# R9A09G057H register map
Vendor: Renesas Electronics; File version: 1.00
CPU: other r0p3, little endian, MPU, FPU, vendor SysTick, 4 interrupt priority bits, 480 interrupts
Registers are 32-bit, read-write, no defined reset value unless marked. A register's access mark holds for its fields unless they carry their own. Offsets are from the block's base; [hi:lo] are bit positions; lines under a group give offsets from that group; {n}, {i} and the like mark numbered series.

## R_SCIFA0 — IO define file for scifa.
Base 0x11C01400
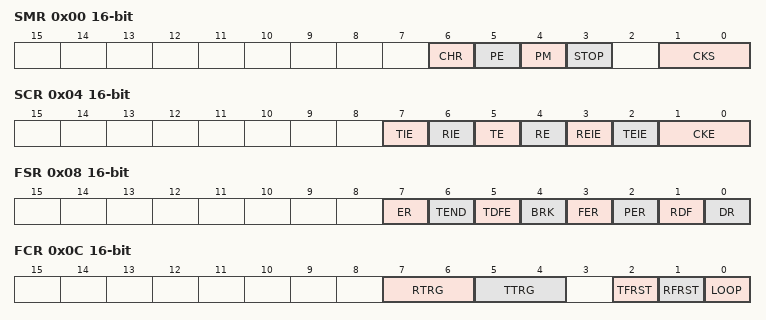
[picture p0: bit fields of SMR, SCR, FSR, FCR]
0x00 SMR 16-bit
  [6] CHR, [5] PE, [4] PM, [3] STOP, [1:0] CKS
0x02 MDDR 8-bit
0x02 BRR 8-bit
0x04 SCR 16-bit
  [7] TIE, [6] RIE, [5] TE, [4] RE, [3] REIE, [2] TEIE, [1:0] CKE
0x06 FTDR 8-bit wo
0x08 FSR 16-bit
  [7] ER, [6] TEND, [5] TDFE, [4] BRK, [3] FER ro, [2] PER ro, [1] RDF, [0] DR
0x0A FRDR 8-bit ro
0x0C FCR 16-bit
  [7:6] RTRG, [5:4] TTRG, [2] TFRST, [1] RFRST, [0] LOOP
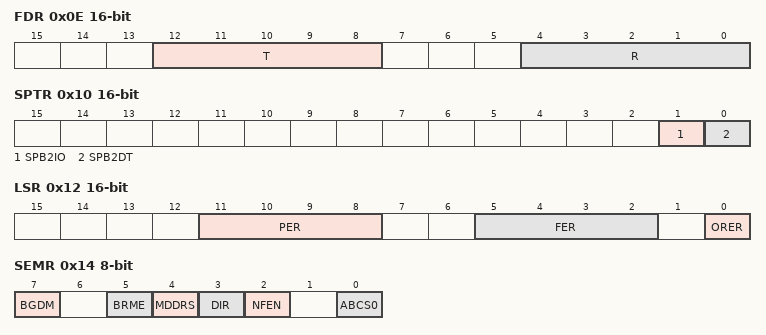
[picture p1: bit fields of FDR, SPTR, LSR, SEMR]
0x0E FDR 16-bit ro
  [12:8] T, [4:0] R
0x10 SPTR 16-bit
  [1] SPB2IO, [0] SPB2DT
0x12 LSR 16-bit
  [11:8] PER ro, [5:2] FER ro, [0] ORER
0x14 SEMR 8-bit
  [7] BGDM, [5] BRME, [4] MDDRS, [3] DIR, [2] NFEN, [0] ABCS0
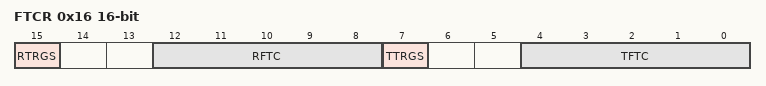
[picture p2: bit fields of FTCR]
0x16 FTCR 16-bit
  [15] RTRGS, [12:8] RFTC, [7] TTRGS, [4:0] TFTC

## R_SPIBSC — IO define file for spibsc.
Base 0x40060000
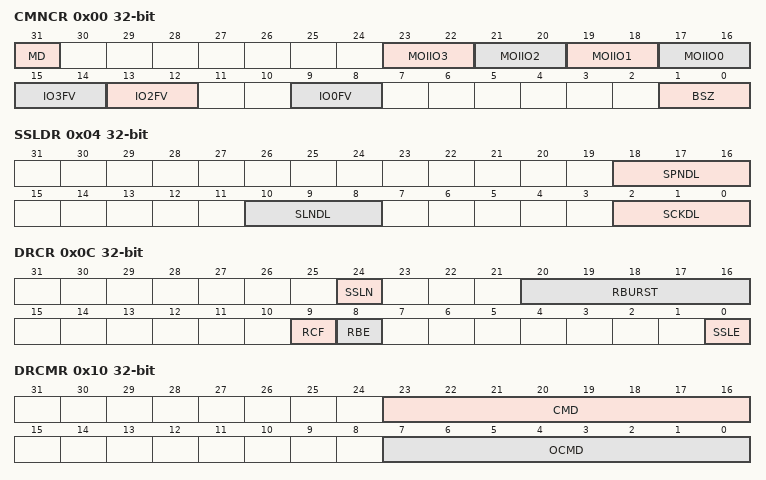
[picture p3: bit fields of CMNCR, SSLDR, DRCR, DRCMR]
0x00 CMNCR
  [31] MD, [2n+17:2n+16] MOIIO{n} (n=0..3), [15:14] IO3FV, [13:12] IO2FV, [9:8] IO0FV, [1:0] BSZ
0x04 SSLDR
  [18:16] SPNDL, [10:8] SLNDL, [2:0] SCKDL
0x0C DRCR
  [24] SSLN wo, [20:16] RBURST, [9] RCF wo, [8] RBE, [0] SSLE
0x10 DRCMR
  [23:16] CMD, [7:0] OCMD
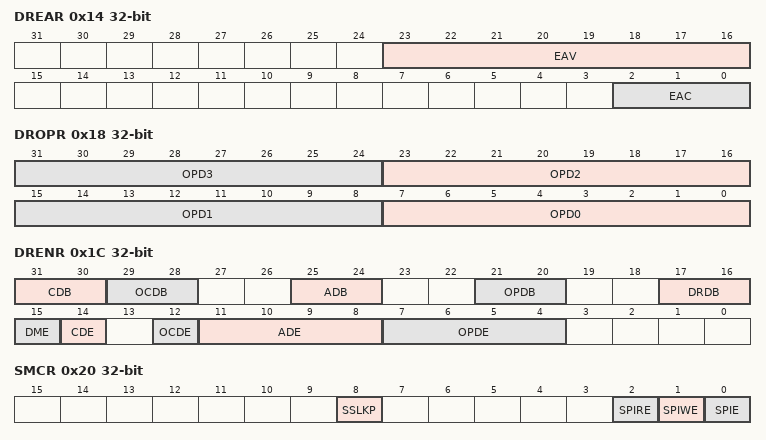
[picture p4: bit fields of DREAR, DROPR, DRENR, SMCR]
0x14 DREAR
  [23:16] EAV, [2:0] EAC
0x18 DROPR
  [8n+7:8n] OPD{n} (n=0..3)
0x1C DRENR
  [31:30] CDB, [29:28] OCDB, [25:24] ADB, [21:20] OPDB, [17:16] DRDB, [15] DME, [14] CDE, [12] OCDE, [11:8] ADE, [7:4] OPDE
0x20 SMCR
  [8] SSLKP, [2] SPIRE, [1] SPIWE, [0] SPIE wo
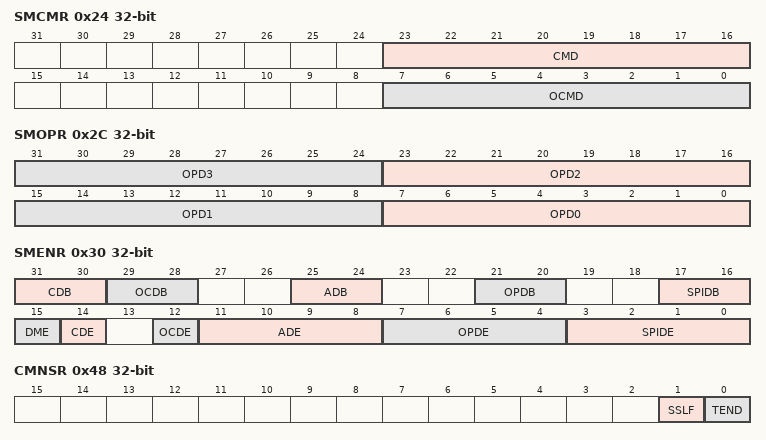
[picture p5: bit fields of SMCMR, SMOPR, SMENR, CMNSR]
0x24 SMCMR
  [23:16] CMD, [7:0] OCMD
0x28 SMADR
  [31:0] ADR
0x2C SMOPR
  [8n+7:8n] OPD{n} (n=0..3)
0x30 SMENR
  [31:30] CDB, [29:28] OCDB, [25:24] ADB, [21:20] OPDB, [17:16] SPIDB, [15] DME, [14] CDE, [12] OCDE, [11:8] ADE, [7:4] OPDE, [3:0] SPIDE
0x38 SMRDR0 ro
  [31:0] RDATA0
0x38 SMRDR0_hword group — SMRDR0_hword register group
  0x00 L 16-bit ro
  0x02 H 16-bit ro
0x38 SMRDR0_byte group — SMRDR0_byte register group
  0x00 LL 8-bit ro
  0x01 LH 8-bit ro
  0x02 HL 8-bit ro
  0x03 HH 8-bit ro
0x3C SMRDR1 ro
  [31:0] RDATA1
0x3C SMRDR1_hword group — SMRDR1_hword register group
  0x00 L 16-bit ro
  0x02 H 16-bit ro
0x3C SMRDR1_byte group — SMRDR1_byte register group
  0x00 LL 8-bit ro
  0x01 LH 8-bit ro
  0x02 HL 8-bit ro
  0x03 HH 8-bit ro
0x40 SMWDR0
  [31:0] WDATA0
0x40 SMWDR0_hword group — SMWDR0_hword register group
  0x00 L 16-bit
  0x02 H 16-bit
0x40 SMWDR0_byte group — SMWDR0_byte register group
  0x00 LL 8-bit
  0x01 LH 8-bit
  0x02 HL 8-bit
  0x03 HH 8-bit
0x44 SMWDR1
  [31:0] WDATA1
0x44 SMWDR1_hword group — SMWDR1_hword register group
  0x00 L 16-bit
  0x02 H 16-bit
0x44 SMWDR1_byte group — SMWDR1_byte register group
  0x00 LL 8-bit
  0x01 LH 8-bit
  0x02 HL 8-bit
  0x03 HH 8-bit
0x48 CMNSR ro
  [1] SSLF, [0] TEND
0x58 DRDMCR
  [4:0] DMCYC
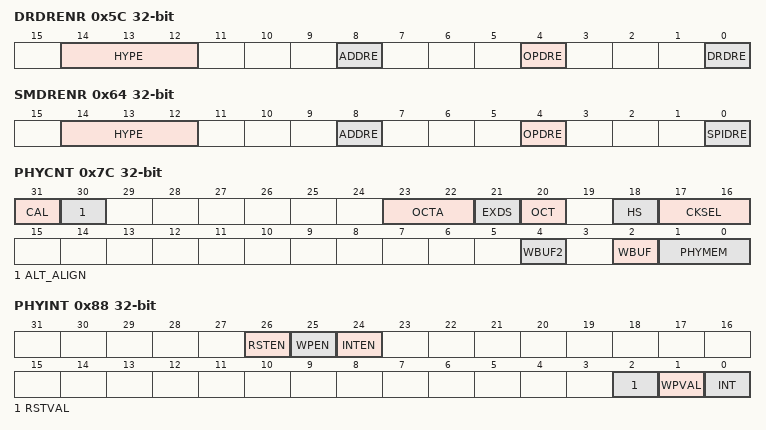
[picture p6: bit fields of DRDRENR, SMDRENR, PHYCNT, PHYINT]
0x5C DRDRENR
  [14:12] HYPE, [8] ADDRE, [4] OPDRE, [0] DRDRE
0x60 SMDMCR
  [4:0] DMCYC
0x64 SMDRENR
  [14:12] HYPE, [8] ADDRE, [4] OPDRE, [0] SPIDRE
0x70 PHYADJ1
  [31:0] ADJ1
0x74 PHYADJ2
  [31:0] ADJ2
0x7C PHYCNT
  [31] CAL wo, [30] ALT_ALIGN, [23:22] OCTA, [21] EXDS, [20] OCT, [18] HS, [17:16] CKSEL, [4] WBUF2, [2] WBUF, [1:0] PHYMEM
0x80 PHYOFFSET1
  [29:28] DDRTMG
0x84 PHYOFFSET2
  [10:8] OCTTMG
0x88 PHYINT
  [26] RSTEN, [25] WPEN, [24] INTEN, [2] RSTVAL, [1] WPVAL, [0] INT ro

## R_SSI0 — IO define file for ssi.
Base 0x40049C00
Same registers: R_SSI1 0x4004A000, R_SSI2 0x4004A400, R_SSI3 0x4004A800
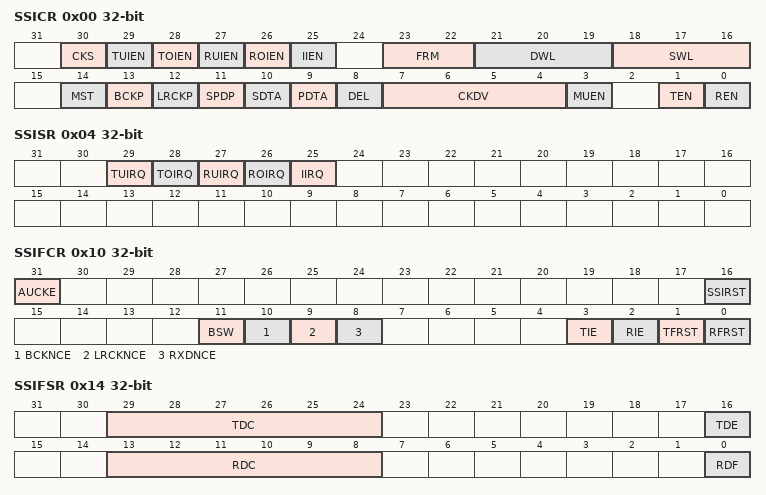
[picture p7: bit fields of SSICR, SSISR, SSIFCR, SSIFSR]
0x00 SSICR
  [30] CKS, [29] TUIEN, [28] TOIEN, [27] RUIEN, [26] ROIEN, [25] IIEN, [23:22] FRM, [21:19] DWL, [18:16] SWL, [14] MST, [13] BCKP, [12] LRCKP, [11] SPDP, [10] SDTA, [9] PDTA, [8] DEL, [7:4] CKDV, [3] MUEN, [1] TEN, [0] REN
0x04 SSISR
  [29] TUIRQ, [28] TOIRQ, [27] RUIRQ, [26] ROIRQ, [25] IIRQ
0x10 SSIFCR
  [31] AUCKE, [16] SSIRST, [11] BSW, [10] BCKNCE, [9] LRCKNCE, [8] RXDNCE, [3] TIE, [2] RIE, [1] TFRST, [0] RFRST
0x14 SSIFSR
  [29:24] TDC ro, [16] TDE, [13:8] RDC ro, [0] RDF
0x18 SSIFTDR wo
0x18 SSIFTDR_hword group — SSIFTDR_hword register group
  0x00 L 16-bit wo
  0x02 H 16-bit wo
0x18 SSIFTDR_byte group — SSIFTDR_byte register group
  0x00 LL 8-bit wo
  0x01 LH 8-bit wo
  0x02 HL 8-bit wo
  0x03 HH 8-bit wo
0x1C SSIFRDR ro
0x1C SSIFRDR_hword group — SSIFRDR_hword register group
  0x00 L 16-bit ro
  0x02 H 16-bit ro
0x1C SSIFRDR_byte group — SSIFRDR_byte register group
  0x00 LL 8-bit ro
  0x01 LH 8-bit ro
  0x02 HL 8-bit ro
  0x03 HH 8-bit ro
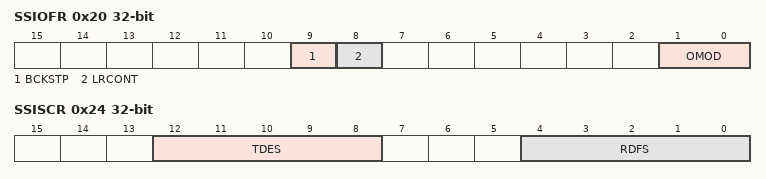
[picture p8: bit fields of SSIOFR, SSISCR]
0x20 SSIOFR
  [9] BCKSTP, [8] LRCONT, [1:0] OMOD
0x24 SSISCR
  [12:8] TDES, [4:0] RDFS
